# apollo510 register map
Vendor: Ambiq Micro; Series: Apollo; File version: 1.0
CPU: CM55 r1p1, little endian, MPU, FPU, double-precision FPU, DSP, I-cache, D-cache, VTOR, ITCM, DTCM, 4 interrupt priority bits, 0 interrupts, 8 SAU regions
Registers are 32-bit, read-write, reset 0x0 unless marked. A register's access mark holds for its fields unless they carry their own. Offsets are from the block's base; [hi:lo] are bit positions; {n}, {i} and the like mark numbered series; 'fields as' and 'values as' point back to an identical list.

## GPU — Graphics Processing Unit
Base 0x40090000
0x00 TEX0BASE — Base address of the drawing surface 0 (must be word aligned).
  [31:0] Base — Address 0: base address of the drawing surface 0 (must be word aligned).
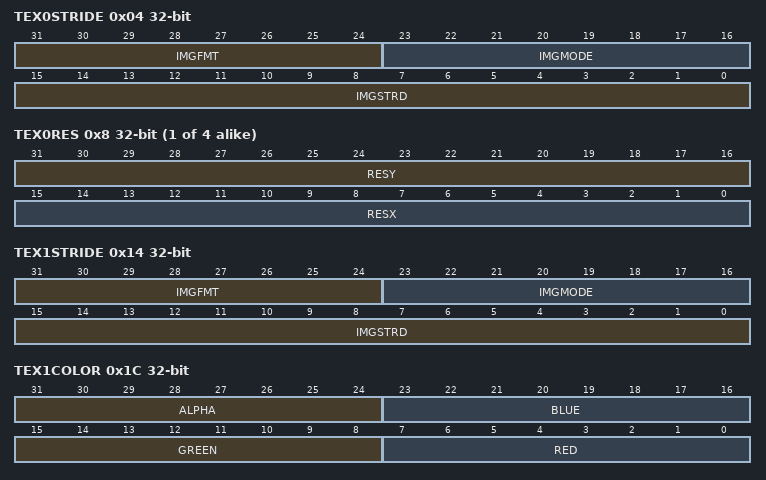
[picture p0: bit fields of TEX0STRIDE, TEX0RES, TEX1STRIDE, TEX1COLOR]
0x04 TEX0STRIDE — Image 0 mode and stride.
  [31:24] IMGFMT — Image Format
    0=RGBX8888 (Color Space RGBX means, that the pixel format still has an alpha channel, but it is ignored, and is always set to 255. The RGBX 32 bit RGB format is stored in memory as 8 red bits, 8 green bits, 8 blue bits, and 8 ignored bits.); 1=RGBA8888 (Color Space RED GREEN BLUE ALPHA (internal format is always on: 32-bit)); 2=XRGB8888 (Color Space); 3=ARGB8888 (Color Space In the ARGB (word-order) encoding the intensity of each channel sample is defined by 8 bits, and are arranged in memory in such manner that a single 32-bit unsigned integer has the alpha sample in the highest 8 bits, followed by the red sample, green sample and finally the blue sample in the lowest 8 bits); 4=RGBA565 (Color Space RED(5-bits) GREEN(6-bits) BLUE (5-bits)); 5=RGBA5551 (Color Space Red,green,blue,alpha (transparency).); 9=L8 (Color Space Lum8 grayscale); 18=TSC4 (Color Space Proprietary texture compression); 22=TSC6 (Color Space Optional proprietary texture compression); 23=TSC6A (Color Space Optional proprietary texture compression)
  [23:16] IMGMODE — Image Mode
    0=POINTSAMPLE (Texture mapping: rotate, resize and distort a bitmap image. Nearest neighbor sampling.); 1=BILINEARFILTERING (Texture mapping: rotate, resize and distort a bitmap image. A method used to smooth textures when displayed larger or smaller than they actually are.)
  [15:0] IMGSTRD — image stride (signed) distance in bytes from one scanline to another
{0x8+0x10*i} TEX{i}RES (i=0..3) — Image {i} resolution.
  [31:16] RESY — resolution Y size
  [15:0] RESX — resolution X size
0x10 TEX1BASE — Base address of the drawing surface 1 (must be word aligned).
  [31:0] Base — address 1: base address of the drawing surface 1 (must be word aligned).
0x14 TEX1STRIDE — Image 1 mode and stride.
  fields as TEX0STRIDE
0x1C TEX1COLOR — Texture maps default color.Used with luminance and alpha-only color formats.
  [31:24] ALPHA — alpha value
  [23:16] BLUE — blue value
  [15:8] GREEN — green value
  [7:0] RED — red value
0x20 TEX2BASE — Base address of the drawing surface 2 (must be word aligned).
  [31:0] Drawing — surface 2 Base address of the drawing surface 2
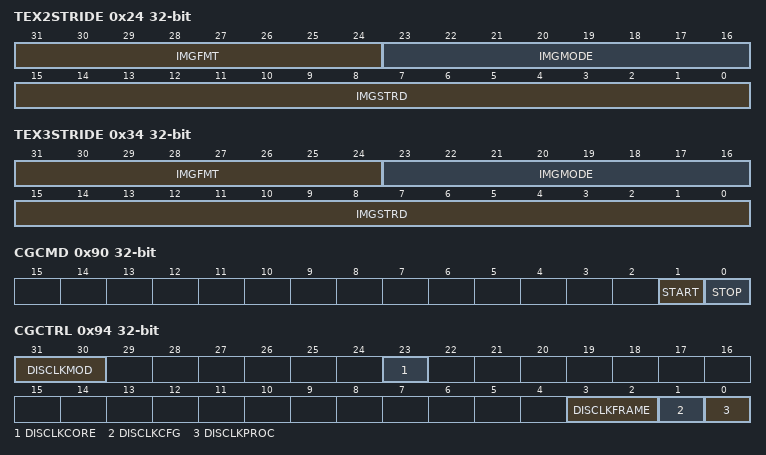
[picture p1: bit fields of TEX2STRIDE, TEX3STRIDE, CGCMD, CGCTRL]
0x24 TEX2STRIDE — Image 2 mode and stride.
  [31:24] IMGFMT — image format
    values as TEX0STRIDE.IMGFMT
  [23:16] IMGMODE — image mode
    values as TEX0STRIDE.IMGMODE
  [15:0] IMGSTRD — image stride (signed) distance in bytes from one scanline to another
0x30 TEX3BASE — Base address of the drawing surface 3 (must be word aligned).
  [31:0] Image — 3 Base address of the drawing surface
0x34 TEX3STRIDE — mode and stride.
  [31:24] IMGFMT — image format
    values as TEX0STRIDE.IMGFMT
  [23:16] IMGMODE — image mode
    0=POINTSAMPLE (Texture mapping: rotate, resize and distort a bitmap image.); 1=BILINEARFILTERING (Texture mapping: rotate, resize and distort a bitmap image. A method used to smooth textures when displayed larger or smaller than they actually are.)
  [15:0] IMGSTRD — image stride (signed) distance in bytes from one scanline to another
0x90 CGCMD — Clock gating enable
  [1] START — start clock
  [0] STOP — stop clock
0x94 CGCTRL — FIXME - register description needed here.
  [31:30] DISCLKMOD — disable clock gating for all modules (MISTAKE ?)
  [23] DISCLKCORE — disable clock gating for core 0
  [3:2] DISCLKFRAME — disable clock gating for framebuffer 0 (MISTAKE ?)
  [1] DISCLKCFG — disable clock gating for configuration file
  [0] DISCLKPROC — disable clock gating for command list processor
0x98 DIRTYTRIGMIN reset 0xFFFFFFFF — Resets dirty region to resolution size when written.
  [31:0] DRTYREG
0x9C DIRTYTRIGMAX — Resets dirty region to resolution size when written.
  [31:0] DRTYREG
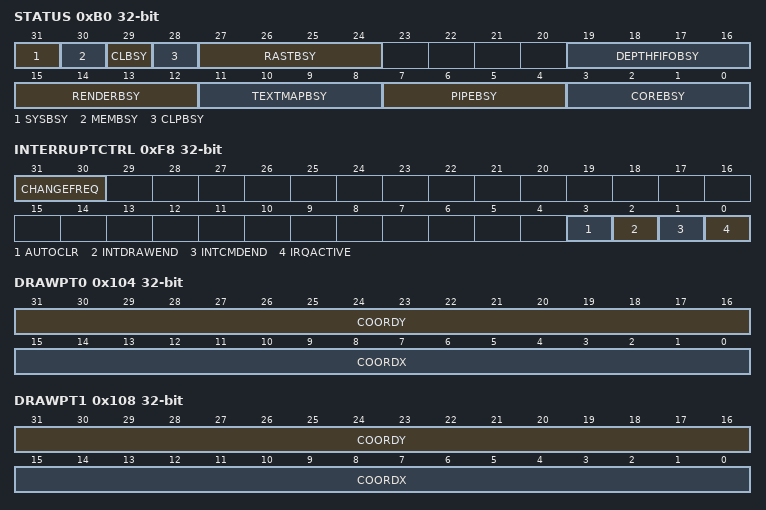
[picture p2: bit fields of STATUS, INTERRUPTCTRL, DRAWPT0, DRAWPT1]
0xB0 STATUS — On read, returns GPU status (CHECK address!!).
  [31] SYSBSY — system busy
  [30] MEMBSY — memory system busy
  [29] CLBSY — command list bus busy
  [28] CLPBSY — command list processor busy
  [27:24] RASTBSY — rasterizer busy
  [19:16] DEPTHFIFOBSY — depth buffer busy (Cores 3-0)
  [15:12] RENDERBSY — render output unit busy (Cores 3-0)
  [11:8] TEXTMAPBSY — texture map busy (Cores 3-0)
  [7:4] PIPEBSY — pipeline busy (Cores 3-0)
  [3:0] COREBSY — processing core busy (Cores 3-0)
0xC0 BUSCTRL — Bus Control
0xC4 IMEMLDIADDR — Load shader instruction memory address.
  [31:0] IMEM — ADDR Load shader. Load shader instruction memory address.
0xC8 IMEMLDIDATAHL — Load shader instruction Memory data (31:0).
  [31:0] IMEM — DATA Load shader. Load shader instruction Memory data (31:0).
0xCC IMEMLDIDATAHH — Load shader instruction Memory data (63:32).
  [31:0] IMEM — DATA Load shader. Load shader instruction Memory data (63:32).
0xE8 CMDLISTSTATUS — On read, returns command list processor status; On write, resets command list processor.
  [0] LIST — processor status
0xEC CMDLISTRINGSTOP — Updates GPU command list pointer to stop executing.
  [31:0] UPDATEPRT
0xF0 CMDLISTADDR — Command list base pointer.
  [31:0] BASEPTR
0xF4 CMDLISTSIZE — Command list length in words.
  [31:0] LISTWORDS
0xF8 INTERRUPTCTRL — On write, clears the IRQ (CHECK address!).
  [31:30] CHANGEFREQ — change frequency of asynchronous clock
  [3] AUTOCLR — if set, auto clears interrupt
  [2] INTDRAWEND — if set, signals interrupt at the end of drawing command
  [1] INTCMDEND — if set, signals interrupt at the end of command list
  [0] IRQACTIVE — if set to zero IRQ is active high, if set to one IRQ is active low
0xFC SYSCLEAR — On write, resets the GPU (CHECK address!).
  [31:0] RESETGPU
0x100 DRAWCMD — Rasterizer drawing command.
  [2:0] START — Start the draw command
    0=PIXEL (draw pixel using STARTXY); 1=LINE (draw line from STARTXY to ENDXY); 2=RECT (fill rectangle from STARTXY to ENDXY); 3=TRI (draw triangle (if enabled)); 4=QUAD (draw quadrilateral (if enabled))
0x104 DRAWPT0 — Stores only integer values. For greater accurancy DRAWPT0X and DRAWPT0Y registers are used which are 16, 16 fixed point.
  [31:16] COORDY — vertex 0 Y coordinate (integer value)
  [15:0] COORDX — vertex 0 X coordinate (integer value)
0x108 DRAWPT1 — Stores only integer values. Vertex 1 drawing primitive. Stores only integer values. For greater accurancy DRAWPT1X and DRAWPT1Y registers are used which are 16, 16 fixed point.
  fields as DRAWPT0
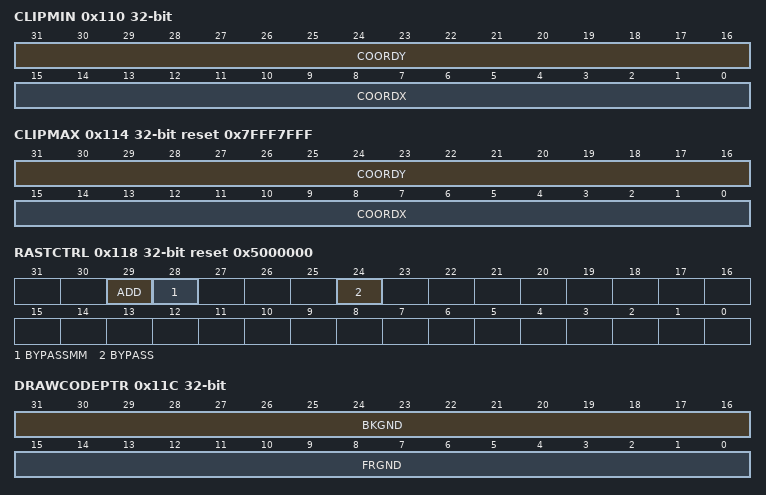
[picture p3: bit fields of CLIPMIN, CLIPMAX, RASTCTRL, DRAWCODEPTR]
0x110 CLIPMIN — Clipping rectangle upper left vertex.
  [31:16] COORDY — upper left Y coordinate
  [15:0] COORDX — upper left X coordinate
0x114 CLIPMAX reset 0x7FFF7FFF — Clipping rectangle bottom right vertex.
  [31:16] COORDY — bottom right Y coordinate
  [15:0] COORDX — bottom right X coordinate
0x118 RASTCTRL reset 0x5000000 — Rasterizer matrix multiplication control
  [29] ADD — adds 0.5 to X and Y
  [28] BYPASSMM — BYPASS_MM, matrix multiplications are bypassed
  [24] BYPASS — BYPASS_VMM, vertx matrix multiplications are bypassed
0x11C DRAWCODEPTR — FIXME - register description needed here.
  [31:16] BKGND — the pointer for the instruction that will be executed for background pixel
  [15:0] FRGND — the pointer for the instruction that will be executed for foreground pixel
{0x120+0x10*i} DRAWPT{i}X (i=0..3) — X coordinate of Vertex {i} drawing primitive 16, 16 fixed point.
  [31:0] DRAW{i}X — X coordinate
{0x124+0x10*i} DRAWPT{i}Y (i=0..2) — Y coordinate of Vertex {i} drawing primitive 16, 16 fixed point.
  [31:0] DRAW{i}Y — Y coordinate
0x128 DRAWPT0Z — FIXME - register description needed here.
  [31:0] DRAW0Z — This bitfield is reserved.
0x12C DRAWCOLOR — FIXME - register description needed here.
  [31:0] RASTPRIM — Rasterizer drawing
0x138 DRAWPT1Z — FIXME - register description needed here.
  [31:0] DRAW1Z — This bitfield is reserved.
0x148 DRAWPT2Z reset not defined — FIXME - register description needed here.
0x154 DRAWPT3Y — Y coordinate of Vertex 3 drawing primitive 16, 16 fixed point.
  [31:0] DRAW3Y — Y coordinate.
0x158 DRAWPT3Z — Fixed value (not accessible). Registers 0x160-0x180 are the elements of the 3x3 transformation matrix used for homogeneous conversion from screen coordinates to texture coordinates; the elements are floating points
  [31:0] DRAW3Z — Fixed value (not accessible)
0x160 MM00 — matrix floating point element.
  [31:0] MTX — (0,0). matrix floating point element.
0x164 MM01 — matrix floating point element.
  [31:0] MTX — (0,1). matrix floating point element.
0x168 MM02 — matrix floating point element; sets to unit matrix if previously written element is MM12.
  [31:0] MTX — (0,2). matrix floating point element.
0x16C MM10 — matrix floating point element.
  [31:0] MTX — (1,0). matrix floating point element.
0x170 MM11 — matrix floating point element.
  [31:0] MTX — (1,1). matrix floating point element
0x174 MM12 — matrix floating point element.
  [31:0] MTX — (1,2). matrix floating point element.
0x178 MM20 — matrix floating point element.
  [31:0] MTX — (2,0). matrix floating point element.
0x17C MM21 — matrix floating point element.
  [31:0] MTX — (2,1). matrix floating point element.
0x180 MM22 — matrix floating point element.
  [31:0] MTX — (2,2). matrix floating point element
0x184 DEPTHSTARTL — Depth value of START pixel, (32 low bits fractional.)
  [31:0] DEPTH32LO — Depth value of START pixel
0x188 DEPTHSTARTH — Depth value of START pixel, (32 high bits integral.)
  [31:0] DEPTH32HI — Depth value of START pixel
0x18C DEPTHDXL — Added depth value for each step at x-axis (32 low bits fractional.)
  [31:0] XAXISLO — Added depth value for each step at x-axis
0x190 DEPTHDXH — Added depth value for each step at x-axis (32 high bits integral.)
  [31:0] XAXISHI — Added depth value for each step at x-axis
0x194 DEPTHDYL — Added depth value for each step at y-axis (32 low bits fractional.)
  [31:0] YAXISLO — Added depth value for each step at y-axis
0x198 DEPTHDYH — Added depth value for each step at y-axis (32 high bits integral.)
  [31:0] YAXISHI — Added depth value for each step at y-axis
0x1A0 REDX — Added red value for each step at x-axis, (16, 16 fixed point)
  [31:0] REDX — Added red value for each step at x-axis
0x1A4 REDY — Added red value for each step at y-axis, (16, 16 fixed point)
  [31:0] REDY — red value for each step at y-axis
0x1A8 GREENX — Added green value for each step at x-axis, (16, 16 fixed point)
  [31:0] GREENX — Added green value for each step at x-axis
0x1AC GREENY — Added green value for each step at y-axis, (16, 16 fixed point)
  [31:0] GREENY — Added green value for each step at y-axis
0x1B0 BLUEX — Added blue value for each step at x-axis, (16, 16 fixed point)
  [31:0] BLUEX — Added blue value for each step at x-axis
0x1B4 BLUEY — Added blue value for each step at y-axis, (16, 16 fixed point)
  [31:0] BLUEY — Added blue value for each step at y-axis
0x1B8 ALFX — Added alfa value for each step at x-axis, (16, 16 fixed point)
  [31:0] ALFX — Added alfa value for each step at x-axis
0x1BC ALFY — Added alfa value for each step at y-axis, (16, 16 fixed point)
  [31:0] ALFY — Added alfa value for each step at y-axis
0x1C0 REDINIT — Red value of STARTXY pixel, (16, 16 fixed point)
  [31:0] REDXY — Red value of STARTXY pixel
0x1C4 GREINIT — Green value of STARTXY pixel, (16, 16 fixed point)
  [31:0] GREENXY — Green value of STARTXY pixel
0x1C8 BLUINIT — Blue value of STARTXY pixel, (16, 16 fixed point)
  [31:0] BLUEXY — Blue value of STARTXY pixel
0x1CC ALFINIT — Alfa value of STARTXY pixel, (16, 16 fixed point) Shader Registers
  [31:0] ALFXY — Alfa value of STARTXY pixel
0x1EC IDREG reset 0x86362000 — Fixed value
  [31:0] GPUID — Fixed value for GPU ID
0x1F0 LOADCTRL reset 0xF4030105 — Load Control
0x200 C0REG — Shader constant register 0.
  [31:0] C0SHADER
0x204 C1REG — Shader constant register 1.
  [31:0] C1SHADER
0x208 C2REG — Shader constant register 2.
  [31:0] C2SHADER — Shader constant register 2
0x20C C3REG — Shader constant register 3, the dirty Region Register
  [31:0] C3SHADER — Shader constant register 3
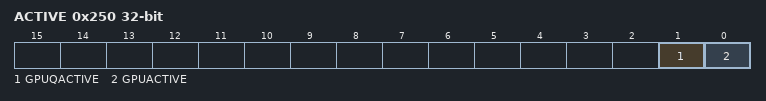
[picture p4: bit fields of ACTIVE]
0x250 ACTIVE — active status
  [1] GPUQACTIVE — GPU QActive status
  [0] GPUACTIVE — GPU active status
0xFF0 IRQID — Signals interrupt when set (CHECK address!).
  [31:0] IRQID — Signals interrupt when set (CHECK address!
